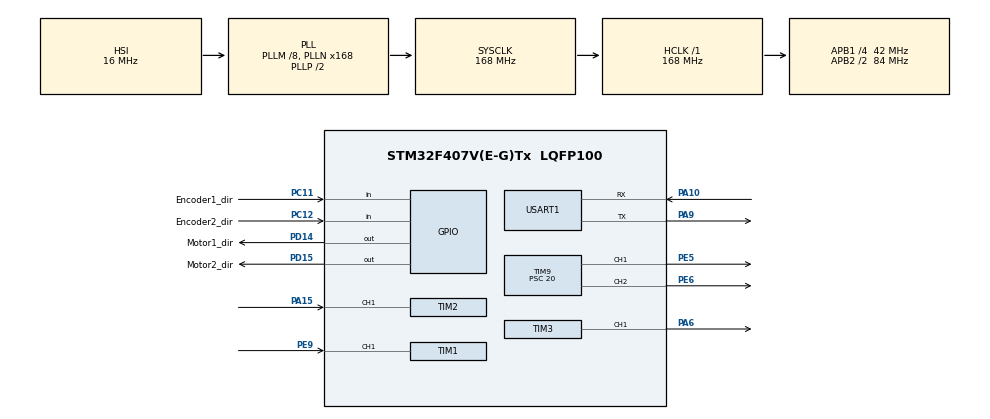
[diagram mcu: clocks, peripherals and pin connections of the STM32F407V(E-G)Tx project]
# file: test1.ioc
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Dma.Request0=USART1_RX
Dma.Request1=USART1_TX
Dma.USART1_RX.0.Direction=DMA_PERIPH_TO_MEMORY
Dma.USART1_RX.0.FIFOMode=DMA_FIFOMODE_DISABLE
Dma.USART1_RX.0.Instance=DMA2_Stream2
Dma.USART1_RX.0.MemDataAlignment=DMA_MDATAALIGN_BYTE
Dma.USART1_RX.0.MemInc=DMA_MINC_ENABLE
Dma.USART1_RX.0.Mode=DMA_NORMAL
Dma.USART1_RX.0.PeriphDataAlignment=DMA_PDATAALIGN_BYTE
Dma.USART1_RX.0.PeriphInc=DMA_PINC_DISABLE
Dma.USART1_RX.0.Priority=DMA_PRIORITY_LOW
Dma.USART1_TX.1.Direction=DMA_MEMORY_TO_PERIPH
Dma.USART1_TX.1.FIFOMode=DMA_FIFOMODE_DISABLE
Dma.USART1_TX.1.Instance=DMA2_Stream7
Dma.USART1_TX.1.MemDataAlignment=DMA_MDATAALIGN_BYTE
Dma.USART1_TX.1.MemInc=DMA_MINC_ENABLE
Dma.USART1_TX.1.Mode=DMA_NORMAL
Dma.USART1_TX.1.PeriphDataAlignment=DMA_PDATAALIGN_BYTE
Dma.USART1_TX.1.PeriphInc=DMA_PINC_DISABLE
Dma.USART1_TX.1.Priority=DMA_PRIORITY_LOW
Mcu.Family=STM32F4
Mcu.Name=STM32F407V(E-G)Tx
Mcu.Package=LQFP100
NVIC.DMA2_Stream2_IRQn=true\:0\:0\:false\:false\:true\:false\:true\:true
NVIC.DMA2_Stream7_IRQn=true\:0\:0\:false\:false\:true\:false\:true\:true
NVIC.PriorityGroup=NVIC_PRIORITYGROUP_4
NVIC.TIM4_IRQn=true\:0\:0\:false\:false\:true\:true\:true\:true
NVIC.USART1_IRQn=true\:0\:0\:false\:false\:true\:true\:true\:true
PA10.Mode=Asynchronous
PA10.Signal=USART1_RX
PA13.Mode=Serial_Wire
PA13.Signal=SYS_JTMS-SWDIO
PA14.Mode=Serial_Wire
PA14.Signal=SYS_JTCK-SWCLK
PA15.Signal=S_TIM2_CH1_ETR
PA6.Signal=S_TIM3_CH1
PA9.Mode=Asynchronous
PA9.Signal=USART1_TX
PC11.GPIO_Label=Encoder1_dir
PC11.Signal=GPIO_Input
PC12.GPIO_Label=Encoder2_dir
PC12.Signal=GPIO_Input
PC14-OSC32_IN.Mode=LSE-External-Oscillator
PC14-OSC32_IN.Signal=RCC_OSC32_IN
PC15-OSC32_OUT.Mode=LSE-External-Oscillator
PC15-OSC32_OUT.Signal=RCC_OSC32_OUT
PD14.GPIO_Label=Motor1_dir
PD14.Signal=GPIO_Output
PD15.GPIO_Label=Motor2_dir
PD15.Signal=GPIO_Output
PE5.Signal=S_TIM9_CH1
PE6.Signal=S_TIM9_CH2
PE9.Signal=S_TIM1_CH1
PH0-OSC_IN.Mode=HSE-External-Oscillator
PH0-OSC_IN.Signal=RCC_OSC_IN
PH1-OSC_OUT.Mode=HSE-External-Oscillator
PH1-OSC_OUT.Signal=RCC_OSC_OUT
ProjectManager.HeapSize=0x200
ProjectManager.StackSize=0x400
ProjectManager.TargetToolchain=CMake
RCC.48MHZClocksFreq_Value=84000000
RCC.AHBFreq_Value=168000000
RCC.APB1CLKDivider=RCC_HCLK_DIV4
RCC.APB1Freq_Value=42000000
RCC.APB1TimFreq_Value=84000000
RCC.APB2CLKDivider=RCC_HCLK_DIV2
RCC.APB2Freq_Value=84000000
RCC.APB2TimFreq_Value=168000000
RCC.CortexFreq_Value=168000000
RCC.HCLKFreq_Value=168000000
RCC.HSE_VALUE=25000000
RCC.HSI_VALUE=16000000
RCC.PLLM=8
RCC.PLLN=168
RCC.SYSCLKFreq_VALUE=168000000
RCC.SYSCLKSource=RCC_SYSCLKSOURCE_PLLCLK
RCC.VCOOutputFreq_Value=336000000
SH.S_TIM1_CH1.0=TIM1_CH1,Input_Capture1_from_TI1
SH.S_TIM2_CH1_ETR.0=TIM2_CH1,Input_Capture1_from_TI1
SH.S_TIM3_CH1.0=TIM3_CH1,PWM Generation1 CH1
SH.S_TIM9_CH1.0=TIM9_CH1,PWM Generation1 CH1
SH.S_TIM9_CH2.0=TIM9_CH2,PWM Generation2 CH2
TIM1.Channel-Input_Capture1_from_TI1=TIM_CHANNEL_1
TIM1.Period=4999
TIM1.Prescaler=4199
TIM2.Channel-Input_Capture1_from_TI1=TIM_CHANNEL_1
TIM2.Period=4999
TIM2.Prescaler=4199
TIM3.Channel-PWM\ Generation1\ CH1=TIM_CHANNEL_1
TIM3.Period=9999
TIM3.Prescaler=83
TIM4.Period=999
TIM4.Prescaler=419
TIM9.Channel-PWM\ Generation1\ CH1=TIM_CHANNEL_1
TIM9.Channel-PWM\ Generation2\ CH2=TIM_CHANNEL_2
TIM9.Period=159
TIM9.Prescaler=20
USART1.VirtualMode=VM_ASYNC
VP_TIM1_VS_ClockSourceINT.Mode=Internal
VP_TIM2_VS_ClockSourceINT.Mode=Internal
VP_TIM4_VS_ClockSourceINT.Mode=Internal
board=custom

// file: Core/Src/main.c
/* USER CODE BEGIN Header */
/**
  ******************************************************************************
  * @file           : main.c
  * @brief          : Main program body
  ******************************************************************************
  * @attention
  *
  * Copyright (c) 2024 STMicroelectronics.
  * All rights reserved.
  *
  * This software is licensed under terms that can be found in the LICENSE file
  * in the root directory of this software component.
  * If no LICENSE file comes with this software, it is provided AS-IS.
  *
  ******************************************************************************
  */
/* USER CODE END Header */
#include "main.h"
#include "dma.h"
#include "tim.h"
#include "usart.h"
#include "gpio.h"

void SystemClock_Config(void);

int main(void)
{

  /* MCU Configuration--------------------------------------------------------*/

  /* Reset of all peripherals, Initializes the Flash interface and the Systick. */
  HAL_Init();

  /* Configure the system clock */
  SystemClock_Config();

  /* Initialize all configured peripherals */
  MX_GPIO_Init();
  MX_DMA_Init();
  MX_TIM1_Init();
  MX_TIM2_Init();
  MX_TIM3_Init();
  MX_TIM4_Init();
  MX_TIM9_Init();
  MX_USART1_UART_Init();
  /* USER CODE BEGIN 2 */
  MOTOR_Init();
  SERVO_Init();
  USB_Init();
  ENCODER_Init();
  /* USER CODE END 2 */

  /* Infinite loop */
  while (1)
  {

  }
}

void SystemClock_Config(void)
{
  RCC_OscInitTypeDef RCC_OscInitStruct = {0};
  RCC_ClkInitTypeDef RCC_ClkInitStruct = {0};

  /** Configure the main internal regulator output voltage
  */
  __HAL_RCC_PWR_CLK_ENABLE();
  __HAL_PWR_VOLTAGESCALING_CONFIG(PWR_REGULATOR_VOLTAGE_SCALE1);

  /** Initializes the RCC Oscillators according to the specified parameters
  * in the RCC_OscInitTypeDef structure.
  */
  RCC_OscInitStruct.OscillatorType = RCC_OSCILLATORTYPE_HSI;
  RCC_OscInitStruct.HSIState = RCC_HSI_ON;
  RCC_OscInitStruct.HSICalibrationValue = RCC_HSICALIBRATION_DEFAULT;
  RCC_OscInitStruct.PLL.PLLState = RCC_PLL_ON;
  RCC_OscInitStruct.PLL.PLLSource = RCC_PLLSOURCE_HSI;
  RCC_OscInitStruct.PLL.PLLM = 8;
  RCC_OscInitStruct.PLL.PLLN = 168;
  RCC_OscInitStruct.PLL.PLLP = RCC_PLLP_DIV2;
  RCC_OscInitStruct.PLL.PLLQ = 4;
  if (HAL_RCC_OscConfig(&RCC_OscInitStruct) != HAL_OK)
  {
    Error_Handler();
  }

  /** Initializes the CPU, AHB and APB buses clocks
  */
  RCC_ClkInitStruct.ClockType = RCC_CLOCKTYPE_HCLK|RCC_CLOCKTYPE_SYSCLK
                              |RCC_CLOCKTYPE_PCLK1|RCC_CLOCKTYPE_PCLK2;
  RCC_ClkInitStruct.SYSCLKSource = RCC_SYSCLKSOURCE_PLLCLK;
  RCC_ClkInitStruct.AHBCLKDivider = RCC_SYSCLK_DIV1;
  RCC_ClkInitStruct.APB1CLKDivider = RCC_HCLK_DIV4;
  RCC_ClkInitStruct.APB2CLKDivider = RCC_HCLK_DIV2;

  if (HAL_RCC_ClockConfig(&RCC_ClkInitStruct, FLASH_LATENCY_5) != HAL_OK)
  {
    Error_Handler();
  }
}

void Error_Handler(void)
{
  __disable_irq();
  while (1)
  {
  }
}
